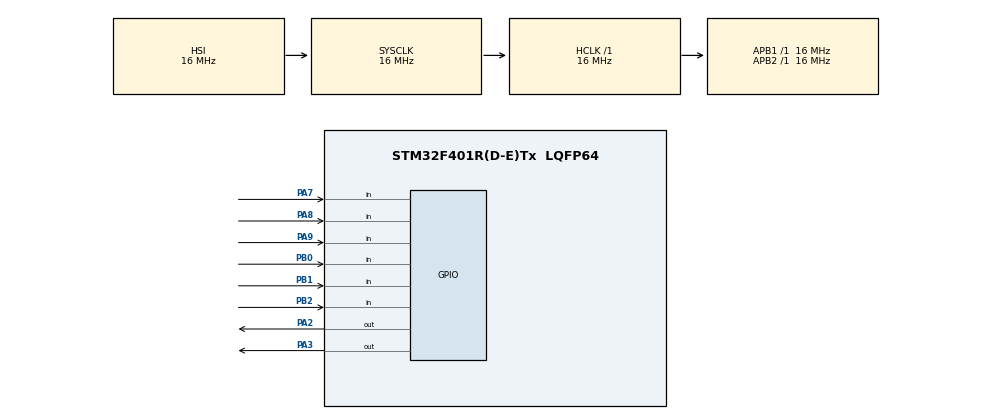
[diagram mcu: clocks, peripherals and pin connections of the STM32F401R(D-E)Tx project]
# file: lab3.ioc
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Mcu.Family=STM32F4
RCC.CortexFreq_Value=16000000
PA9.GPIO_PuPd=GPIO_PULLUP
ProjectManager.StackSize=0x400
ProjectManager.TargetToolchain=STM32CubeIDE
PA9.Signal=GPIO_Input
RCC.LSE_VALUE=32768
PA7.GPIO_PuPd=GPIO_PULLUP
RCC.AHBFreq_Value=16000000
RCC.HSE_VALUE=25000000
PB2.Signal=GPIO_Input
board=custom
RCC.VCOOutputFreq_Value=192000000
RCC.APB2Freq_Value=16000000
PA8.Signal=GPIO_Input
Mcu.Name=STM32F401R(D-E)Tx
PA2.Signal=GPIO_Output
RCC.SYSCLKFreq_VALUE=16000000
Mcu.Package=LQFP64
PB1.Signal=GPIO_Input
ProjectManager.HeapSize=0x200
RCC.HSI_VALUE=16000000
PA8.GPIO_PuPd=GPIO_PULLUP
NVIC.PriorityGroup=NVIC_PRIORITYGROUP_4
RCC.APB1Freq_Value=16000000
PB0.Signal=GPIO_Input
PA3.Signal=GPIO_Output
PA7.Signal=GPIO_Input

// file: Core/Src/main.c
/* USER CODE BEGIN Header */
/**
  ******************************************************************************
  * @file           : main.c
  * @brief          : Main program body
  ******************************************************************************
  * @attention
  *
  * <h2><center>&copy; Copyright (c) 2021 STMicroelectronics.
  * All rights reserved.</center></h2>
  *
  * This software component is licensed by ST under BSD 3-Clause license,
  * the "License"; You may not use this file except in compliance with the
  * License. You may obtain a copy of the License at:
  *                        opensource.org/licenses/BSD-3-Clause
  *
  ******************************************************************************
  */
/* USER CODE END Header */
#include "main.h"

void SystemClock_Config(void);
static void MX_GPIO_Init(void);

int main(void)
{

  /* MCU Configuration--------------------------------------------------------*/

  /* Reset of all peripherals, Initializes the Flash interface and the Systick. */
  HAL_Init();

  /* Configure the system clock */
  SystemClock_Config();

  /* Initialize all configured peripherals */
  MX_GPIO_Init();
  /* USER CODE BEGIN 2 */
  uint8_t state = 0;
  /* USER CODE END 2 */

  /* Infinite loop */
  while (1)
  {

    /* USER CODE BEGIN 3 */
	  if(HAL_GPIO_ReadPin(GPIOA, GPIO_PIN_7) == 0 ){
	  			state = 0;
	  	  		HAL_GPIO_WritePin(GPIOA, GPIO_PIN_3, GPIO_PIN_RESET);
	  	  	    HAL_GPIO_WritePin(GPIOA, GPIO_PIN_2, GPIO_PIN_RESET);
	  }
	  else if (!state && HAL_GPIO_ReadPin(GPIOA, GPIO_PIN_8) == 0) {
		  state = 1;
		  HAL_GPIO_WritePin(GPIOA, GPIO_PIN_3, GPIO_PIN_SET);
	  }
	  else if (!state && HAL_GPIO_ReadPin(GPIOA, GPIO_PIN_9) == 0) {
		  state = 1;
		  HAL_GPIO_WritePin(GPIOA, GPIO_PIN_2, GPIO_PIN_SET);
	  }
  }
  /* USER CODE END 3 */
}

void SystemClock_Config(void)
{
  RCC_OscInitTypeDef RCC_OscInitStruct = {0};
  RCC_ClkInitTypeDef RCC_ClkInitStruct = {0};

  /** Configure the main internal regulator output voltage
  */
  __HAL_RCC_PWR_CLK_ENABLE();
  __HAL_PWR_VOLTAGESCALING_CONFIG(PWR_REGULATOR_VOLTAGE_SCALE2);
  /** Initializes the RCC Oscillators according to the specified parameters
  * in the RCC_OscInitTypeDef structure.
  */
  RCC_OscInitStruct.OscillatorType = RCC_OSCILLATORTYPE_HSI;
  RCC_OscInitStruct.HSIState = RCC_HSI_ON;
  RCC_OscInitStruct.HSICalibrationValue = RCC_HSICALIBRATION_DEFAULT;
  RCC_OscInitStruct.PLL.PLLState = RCC_PLL_NONE;
  if (HAL_RCC_OscConfig(&RCC_OscInitStruct) != HAL_OK)
  {
    Error_Handler();
  }
  /** Initializes the CPU, AHB and APB buses clocks
  */
  RCC_ClkInitStruct.ClockType = RCC_CLOCKTYPE_HCLK|RCC_CLOCKTYPE_SYSCLK
                              |RCC_CLOCKTYPE_PCLK1|RCC_CLOCKTYPE_PCLK2;
  RCC_ClkInitStruct.SYSCLKSource = RCC_SYSCLKSOURCE_HSI;
  RCC_ClkInitStruct.AHBCLKDivider = RCC_SYSCLK_DIV1;
  RCC_ClkInitStruct.APB1CLKDivider = RCC_HCLK_DIV1;
  RCC_ClkInitStruct.APB2CLKDivider = RCC_HCLK_DIV1;

  if (HAL_RCC_ClockConfig(&RCC_ClkInitStruct, FLASH_LATENCY_0) != HAL_OK)
  {
    Error_Handler();
  }
}

static void MX_GPIO_Init(void)
{
  GPIO_InitTypeDef GPIO_InitStruct = {0};

  /* GPIO Ports Clock Enable */
  __HAL_RCC_GPIOA_CLK_ENABLE();
  __HAL_RCC_GPIOB_CLK_ENABLE();

  /*Configure GPIO pin Output Level */
  HAL_GPIO_WritePin(GPIOA, GPIO_PIN_2|GPIO_PIN_3, GPIO_PIN_RESET);

  /*Configure GPIO pins : PA2 PA3 */
  GPIO_InitStruct.Pin = GPIO_PIN_2|GPIO_PIN_3;
  GPIO_InitStruct.Mode = GPIO_MODE_OUTPUT_PP;
  GPIO_InitStruct.Pull = GPIO_NOPULL;
  GPIO_InitStruct.Speed = GPIO_SPEED_FREQ_LOW;
  HAL_GPIO_Init(GPIOA, &GPIO_InitStruct);

  /*Configure GPIO pins : PA7 PA8 PA9 */
  GPIO_InitStruct.Pin = GPIO_PIN_7|GPIO_PIN_8|GPIO_PIN_9;
  GPIO_InitStruct.Mode = GPIO_MODE_INPUT;
  GPIO_InitStruct.Pull = GPIO_PULLUP;
  HAL_GPIO_Init(GPIOA, &GPIO_InitStruct);

  /*Configure GPIO pins : PB0 PB1 PB2 */
  GPIO_InitStruct.Pin = GPIO_PIN_0|GPIO_PIN_1|GPIO_PIN_2;
  GPIO_InitStruct.Mode = GPIO_MODE_INPUT;
  GPIO_InitStruct.Pull = GPIO_NOPULL;
  HAL_GPIO_Init(GPIOB, &GPIO_InitStruct);

}

void Error_Handler(void)
{
  __disable_irq();
  while (1)
  {
  }
}

/************************ (C) COPYRIGHT STMicroelectronics *****END OF FILE****/
